# STM32L15xxxA register map
File version: 1.0
CPU: 
Registers are 32-bit, read-write, reset 0x0 unless marked. A register's access mark holds for its fields unless they carry their own. Offsets are from the block's base; [hi:lo] are bit positions; {n}, {i} and the like mark numbered series.

## SYSCFG — System configuration controller
Base 0x40010000
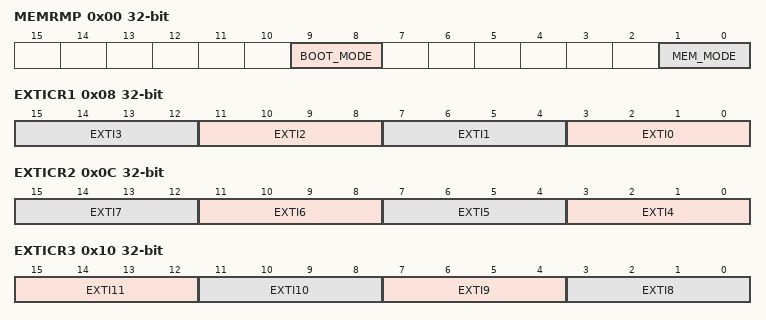
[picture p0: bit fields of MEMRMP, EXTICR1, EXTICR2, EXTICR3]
0x00 MEMRMP access per field — memory remap register
  [9:8] BOOT_MODE ro, [1:0] MEM_MODE rw
0x04 PMC — peripheral mode configuration register
  [0] USB_PU — USB pull-up
0x08 EXTICR1 — external interrupt configuration register 1
  [4n+3:4n] EXTI{n} (n=0..3) — EXTI x configuration (x = 0 to 3)
0x0C EXTICR2 — external interrupt configuration register 2
  [4n-13:4n-16] EXTI{n} (n=4..7) — EXTI x configuration (x = 4 to 7)
0x10 EXTICR3 — external interrupt configuration register 3
  [15:12] EXTI11 — EXTI x configuration (x = 8 to 11)
  [11:8] EXTI10
  [7:4] EXTI9 — EXTI x configuration (x = 8 to 11)
  [3:0] EXTI8 — EXTI x configuration (x = 8 to 11)
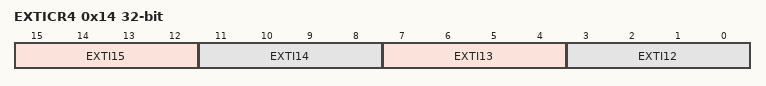
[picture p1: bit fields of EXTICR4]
0x14 EXTICR4 — external interrupt configuration register 4
  [15:12] EXTI15 — EXTI x configuration (x = 12 to 15)
  [11:8] EXTI14
  [7:4] EXTI13
  [3:0] EXTI12

## TIM10 — General-purpose timers
Base 0x40010C00
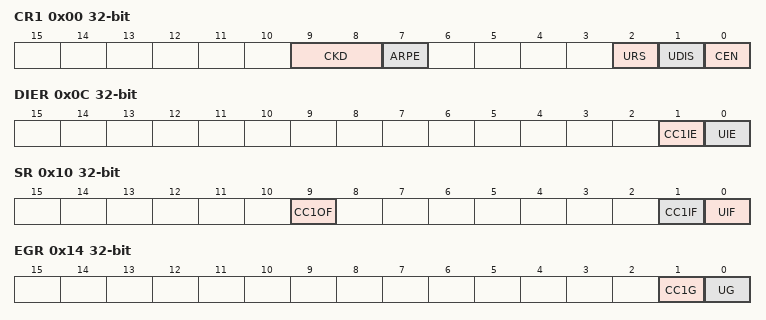
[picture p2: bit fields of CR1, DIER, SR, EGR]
0x00 CR1 — control register 1
  [9:8] CKD — Clock division
  [7] ARPE — Auto-reload preload enable
  [2] URS — Update request source
  [1] UDIS — Update disable
  [0] CEN — Counter enable
0x0C DIER wo — Interrupt enable register
  [1] CC1IE — Capture/Compare 1 interrupt enable
  [0] UIE — Update interrupt enable
0x10 SR — status register
  [9] CC1OF — Capture/compare 1 overcapture flag
  [1] CC1IF — Capture/Compare 1 interrupt flag
  [0] UIF — Update interrupt flag
0x14 EGR — event generation register
  [1] CC1G — Capture/Compare 1 generation
  [0] UG — Update generation
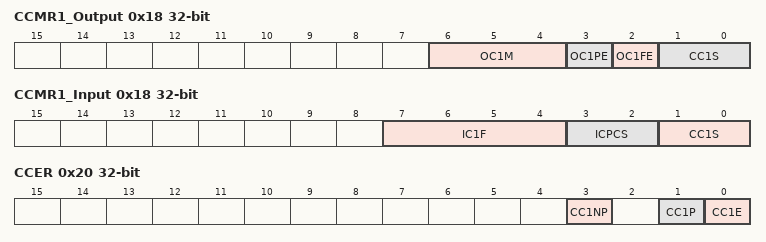
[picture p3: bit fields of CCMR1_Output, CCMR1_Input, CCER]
0x18 CCMR1_Output — capture/compare mode register
  [6:4] OC1M — Output compare 1 mode
  [3] OC1PE — Output compare 1 preload enable
  [2] OC1FE — Output compare 1 fast enable
  [1:0] CC1S — Capture/Compare 1 selection
0x18 CCMR1_Input — capture/compare mode register 1 (input mode)
  [7:4] IC1F — Input capture 1 filter
  [3:2] ICPCS — Input capture 1 prescaler
  [1:0] CC1S — Capture/Compare 1 selection
0x20 CCER — capture/compare enable register
  [3] CC1NP — Capture/Compare 1 complementary output Polarity
  [1] CC1P — Capture/Compare 1 output Polarity
  [0] CC1E — Capture/Compare 1 output enable
0x24 CNT — counter
  [15:0] CNT — TIM10 counter
0x28 PSC — prescaler
  [15:0] PSC — TIM9 prescaler
0x2C ARR — auto-reload register
  [15:0] ARR — Auto-reload value
0x34 CCR1 — capture/compare register 1
  [15:0] CCR1 — Capture/Compare 1 value
0x50 OR — option register
  [1:0] TI1_RMP — TIM11 Input 1 remapping capability

## TIM11 — General-purpose timers
Base 0x40011000
Registers as TIM10; these are added or differ:
0x24 CNT — counter
  [15:0] CNT — TIM10 counter
0x50 OR — option register
  [1:0] TI1_RMP — TIM11 Input 1 remapping capability

## TIM6 — Basic timers
Base 0x40001000
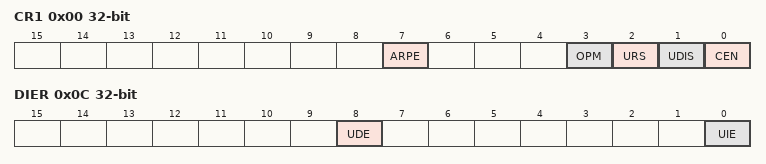
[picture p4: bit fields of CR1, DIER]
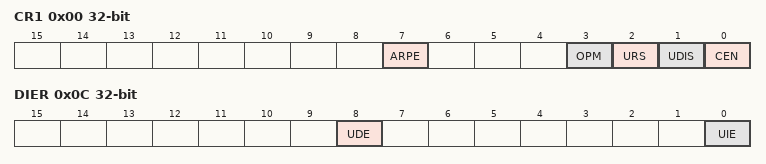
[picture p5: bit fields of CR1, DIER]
0x00 CR1 — TIM6 control register 1
  [7] ARPE — Auto-reload preload enable
  [3] OPM — One-pulse mode
  [2] URS — Update request source
  [1] UDIS — Update disable
  [0] CEN — Counter enable
0x04 CR2 — TIM6 control register 2
  [6:4] MMS — Master mode selection
0x0C DIER — TIM6 DMA/Interrupt enable register
  [8] UDE — Update DMA request enable
  [0] UIE — Update interrupt enable
0x10 SR — TIM6 status register
  [0] UIF — Update interrupt flag
0x14 EGR wo — TIM6 event generation register
  [0] UG — Update generation
0x24 CNT — TIM6 counter
  [15:0] CNT
0x28 PSC — TIM6 prescaler
  [15:0] PSC — Prescaler valueThe counter clock frequency CK_CNT is equal to fCK_PSC / (PSC[15:0] + 1).
0x2C ARR — TIM6 auto-reload register
  [15:0] ARR — Prescaler value

## TIM7 — Basic timers
Base 0x40001400
0x00 CR1 — TIM6 control register 1
  [7] ARPE — Auto-reload preload enable
  [3] OPM — One-pulse mode
  [2] URS — Update request source
  [1] UDIS — Update disable
  [0] CEN — Counter enable
0x04 CR2 — TIM6 control register 2
  [6:4] MMS — Master mode selection
0x0C DIER — TIM6 DMA/Interrupt enable register
  [8] UDE — Update DMA request enable
  [0] UIE — Update interrupt enable
0x10 SR — TIM6 status register
  [0] UIF — Update interrupt flag
0x14 EGR wo — TIM6 event generation register
  [0] UG — Update generation
0x24 CNT — TIM6 counter
  [15:0] CNT
0x28 PSC — TIM6 prescaler
  [15:0] PSC — Prescaler valueThe counter clock frequency CK_CNT is equal to fCK_PSC / (PSC[15:0] + 1).
0x2C ARR — TIM6 auto-reload register
  [15:0] ARR — Prescaler value
